# L3INIT_PRM register map
Vendor: Texas Instruments
Peripheral module from a debugger description file (folder omap4430).
Registers are 32-bit, access not given, reset 0x0 unless marked. A register's access mark holds for its fields unless they carry their own. Offsets are as the file gives them; lines under a group give offsets from that group; [hi:lo] are bit positions; {n}, {i} and the like mark numbered series; 'fields as' and 'values as' point back to an identical list; <NAME> marks a mode.

## L3INIT_PRM
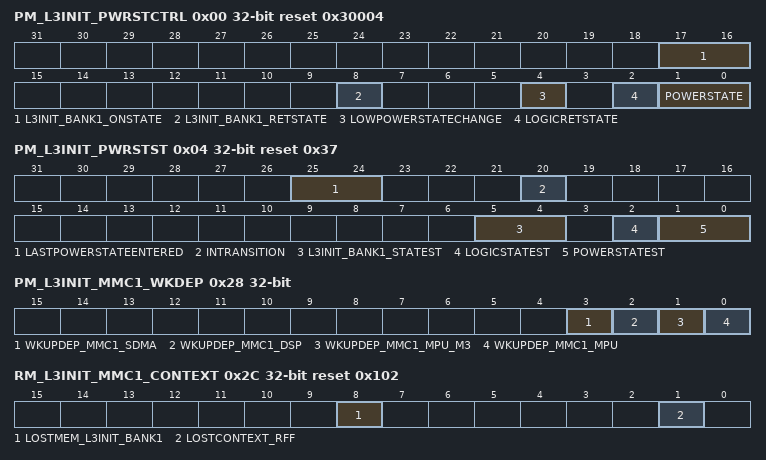
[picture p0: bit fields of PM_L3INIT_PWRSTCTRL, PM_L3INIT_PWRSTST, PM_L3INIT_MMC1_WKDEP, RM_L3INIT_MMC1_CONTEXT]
0x00 PM_L3INIT_PWRSTCTRL reset 0x30004 — This register controls the L3INIT power state to reach upon a domain sleep transition
  [17:16] L3INIT_BANK1_ONSTATE — L3INIT BANK state when domain is ON. (access R Rreturns1s)
    3=L3INIT_BANK1_ONSTATE_3_r (Memory bank is on when the domain is ON.)
  [8] L3INIT_BANK1_RETSTATE ro — L3INIT BANK1 state when domain is RETENTION.
    0=L3INIT_BANK1_RETSTATE_0_r (Memory bank is off when the domain is in the RETENTION state.)
  [4] LOWPOWERSTATECHANGE — Power state change request when domain has already performed a sleep transition. Allows going into deeper low power state without waking up the power domain. (access RW WSpecial)
    0=Do not request a low power state change; 1=Request a low power state change. This bit is automatically cleared when the power state is effectively changed or when power state is ON.
  [2] LOGICRETSTATE rw — Logic state when power domain is RETENTION
    0=Only retention registers are retained and remaing logic is off when the domain is in RETENTION state; 1=Whole logic is retained when domain is in RETENTION state
  [1:0] POWERSTATE rw — Power state control
    0=OFF state; 1=RETENTION state; 2=INACTIVE state; 3=ON State
0x04 PM_L3INIT_PWRSTST reset 0x37 — This register provides a status on the current L3INIT power domain state. [warm reset insensitive]
  [25:24] LASTPOWERSTATEENTERED — Last low power state entered. Set to 0x3 upon write of the same only. This register is intended for debug purpose only. (access RW W1toSet)
    3=LASTPOWERSTATEENTERED_3_r (Power domain was previously ON-ACTIVE); 2=LASTPOWERSTATEENTERED_2_r (Power domain was previously ON-INACTIVE); 1=LASTPOWERSTATEENTERED_1_r (Power domain was previously in RETENTION); 0=LASTPOWERSTATEENTERED_0_r (Power domain was previously OFF)
  [20] INTRANSITION ro — Domain transition status
    0=INTRANSITION_0_r (No ongoing transition on power domain); 1=INTRANSITION_1_r (Power domain transition is in progress.)
  [5:4] L3INIT_BANK1_STATEST ro — L3INIT BANK1 state status
    0=L3INIT_BANK1_STATEST_0_r (Memory is OFF); 1=L3INIT_BANK1_STATEST_1_r (Reserved); 2=L3INIT_BANK1_STATEST_2_r (Reserved); 3=L3INIT_BANK1_STATEST_3_r (Memory is ON)
  [2] LOGICSTATEST ro — Logic state status
    0=LOGICSTATEST_0_r (Logic in domain is OFF); 1=LOGICSTATEST_1_r (Logic in domain is ON)
  [1:0] POWERSTATEST ro — Current power state status
    0=POWERSTATEST_0_r (Power domain is OFF); 1=POWERSTATEST_1_r (Power domain is in RETENTION); 2=POWERSTATEST_2_r (Power domain is ON-INACTIVE); 3=POWERSTATEST_3_r (Power domain is ON-ACTIVE)
0x28 PM_L3INIT_MMC1_WKDEP access per field — This register controls wakeup dependency based on MMC1 service requests.
  [all] fields
    0=Dependency is disabled; 1=Dependency is enabled
  [3] WKUPDEP_MMC1_SDMA rw — Wakeup dependency from MMC1 module (softwareakeup signal) towards SDMA + L3_2 + L4PER domains
  [2] WKUPDEP_MMC1_DSP rw — Wakeup dependency from MMC1 module (softwareakeup signal) towards DSP + L3_1 + L3_2 + L4_PER domains
  [1] WKUPDEP_MMC1_MPU_M3 rw — Wakeup dependency from MMC1 module (softwareakeup signal) towards MPU_A3 + L3_2 + L4_PER domains
  [0] WKUPDEP_MMC1_MPU rw — Wakeup dependency from MMC1 module (softwareakeup signal) towards MPU + L3_1 + L3_2 + L4_PER domains
0x2C RM_L3INIT_MMC1_CONTEXT reset 0x102 — This register contains dedicated MMC1 context statuses. [warm reset insensitive]
  [8] LOSTMEM_L3INIT_BANK1 — Specify if memory-based context in L3INIT_BANK1 memory bank has been lost due to a previous power transition or other reset source. (access RW W1toClr)
    0=Context has been maintained; 1=Context has been lost
  [1] LOSTCONTEXT_RFF — Specify if RFF-based context has been lost due to a previous power transition or other reset source. (set upon assertion of L3_INIT_RET_RST signal) (access RW W1toClr)
    0=Context has been maintained; 1=Context has been lost
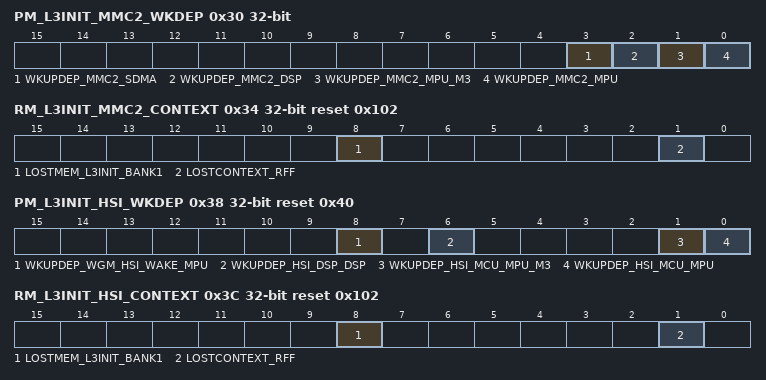
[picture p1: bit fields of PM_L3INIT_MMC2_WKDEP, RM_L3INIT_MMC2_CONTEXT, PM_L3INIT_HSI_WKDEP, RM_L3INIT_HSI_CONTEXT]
0x30 PM_L3INIT_MMC2_WKDEP access per field — This register controls wakeup dependency based on MMC2 service requests.
  [all] fields
    0=Dependency is disabled; 1=Dependency is enabled
  [3] WKUPDEP_MMC2_SDMA rw — Wakeup dependency from MMC2 module (softwareakeup signal) towards SDMA + L3_2 + L4PER domains
  [2] WKUPDEP_MMC2_DSP rw — Wakeup dependency from MMC2 module (softwareakeup signal) towards DSP + L3_1 + L3_2 + L4_PER domains
  [1] WKUPDEP_MMC2_MPU_M3 rw — Wakeup dependency from MMC2 module (softwareakeup signal) towards MPU_A3 + L3_2 + L4_PER domains
  [0] WKUPDEP_MMC2_MPU rw — Wakeup dependency from MMC2 module (softwareakeup signal) towards MPU + L3_1 + L3_2 + L4_PER domains
0x34 RM_L3INIT_MMC2_CONTEXT reset 0x102 — This register contains dedicated MMC2 context statuses. [warm reset insensitive]
  fields as RM_L3INIT_MMC1_CONTEXT
0x38 PM_L3INIT_HSI_WKDEP reset 0x40 — This register controls wakeup dependency based on HSI service requests.
  [8] WKUPDEP_WGM_HSI_WAKE_MPU rw — Wakeup dependency from modem HSI_WAKE signal towards MPU + L3_1 + L4_CFG domains
    0=Dependency is disabled; 1=Dependency is enabled
  [6] WKUPDEP_HSI_DSP_DSP — Wakeup dependency from HSI module (softwareakeup_DSP signal) towards DSP + L3_1 + L4_CFG domains (access R Rreturns1s)
    1=WKUPDEP_HSI_DSP_DSP_1_r (Dependency is enabled)
  [1] WKUPDEP_HSI_MCU_MPU_M3 rw — Wakeup dependency from HSI module (softwareakeup_MPU signal) towards MPU_A3 + L3_2 + L3_1 + L4_CFG domains
    0=Dependency is disabled; 1=Dependency is enabled
  [0] WKUPDEP_HSI_MCU_MPU rw — Wakeup dependency from HSI module (softwareakeup_MPU signal) towards MPU + L3_1 + L4_CFG domains
    0=Dependency is disabled; 1=Dependency is enabled
0x3C RM_L3INIT_HSI_CONTEXT reset 0x102 — This register contains dedicated HSI context statuses. [warm reset insensitive]
  fields as RM_L3INIT_MMC1_CONTEXT
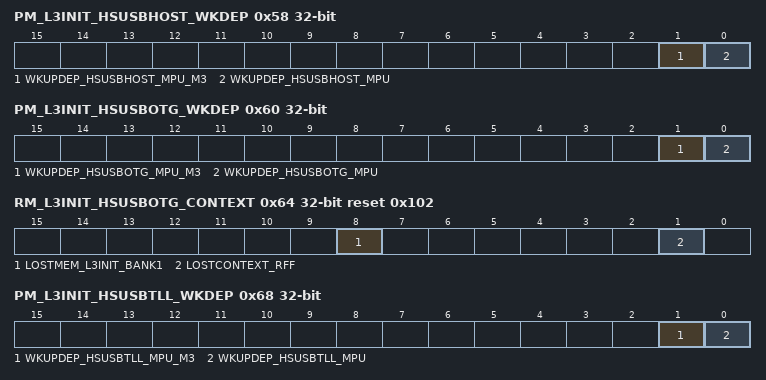
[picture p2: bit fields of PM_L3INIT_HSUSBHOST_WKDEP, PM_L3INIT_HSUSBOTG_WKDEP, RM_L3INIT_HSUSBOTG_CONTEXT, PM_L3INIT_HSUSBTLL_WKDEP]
0x58 PM_L3INIT_HSUSBHOST_WKDEP access per field — This register controls wakeup dependency based on USB_HOST_HS service requests.
  [1] WKUPDEP_HSUSBHOST_MPU_M3 rw — Wakeup dependency from USB_HOST_HS module (softwareakeup signal) towards MPU_A3 + L3_2 + L3_1 + L4_CFG domains
    0=Dependency is disabled; 1=Dependency is enabled
  [0] WKUPDEP_HSUSBHOST_MPU rw — Wakeup dependency from USB_HOST_HS module (softwareakeup signal) towards MPU + L3_1 + L4_CFG domains
    0=Dependency is disabled; 1=Dependency is enabled
0x5C RM_L3INIT_HSUSBHOST_CONTEXT reset 0x2 — This register contains dedicated USB_HOST context statuses. [warm reset insensitive]
  [1] LOSTCONTEXT_RFF — Specify if RFF-based context has been lost due to a previous power transition or other reset source. (set upon assertion of L3_INIT_RET_RST signal) (access RW W1toClr)
    0=Context has been maintained; 1=Context has been lost
0x60 PM_L3INIT_HSUSBOTG_WKDEP access per field — This register controls wakeup dependency based on USB_OTG_HS service requests.
  [1] WKUPDEP_HSUSBOTG_MPU_M3 rw — Wakeup dependency from USB_OTG_HS module (softwareakeup signal) towards MPU_A3 + L3_2 + L3_1 + L4_CFG domains
    0=Dependency is disabled; 1=Dependency is enabled
  [0] WKUPDEP_HSUSBOTG_MPU rw — Wakeup dependency from USB_OTG_HS module (softwareakeup signal) towards MPU + L3_1 + L4_CFG domains
    0=Dependency is disabled; 1=Dependency is enabled
0x64 RM_L3INIT_HSUSBOTG_CONTEXT reset 0x102 — This register contains dedicated USB_OTG_HS context statuses. [warm reset insensitive]
  fields as RM_L3INIT_MMC1_CONTEXT
0x68 PM_L3INIT_HSUSBTLL_WKDEP access per field — This register controls wakeup dependency based on USB_TLL service requests.
  [1] WKUPDEP_HSUSBTLL_MPU_M3 rw — Wakeup dependency from USB_TLL module (softwareakeup signal) towards MPU_A3 + L3_2 + L3_1 + L4_CFG domains
    0=Dependency is disabled; 1=Dependency is enabled
  [0] WKUPDEP_HSUSBTLL_MPU rw — Wakeup dependency from USB_TLL module (softwareakeup signal) towards MPU + L3_1 + L4_CFG domains
    0=Dependency is disabled; 1=Dependency is enabled
0x6C RM_L3INIT_HSUSBTLL_CONTEXT reset 0x2 — This register contains dedicated USB_TLL context statuses. [warm reset insensitive]
  fields as RM_L3INIT_HSUSBHOST_CONTEXT
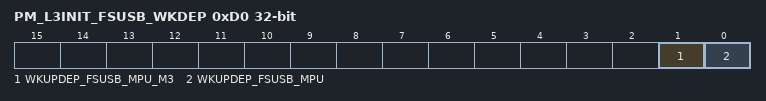
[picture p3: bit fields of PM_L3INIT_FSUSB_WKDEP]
0xD0 PM_L3INIT_FSUSB_WKDEP access per field — This register controls wakeup dependency based on USB_HOST_FS service requests.
  [1] WKUPDEP_FSUSB_MPU_M3 rw — Wakeup dependency from USB_HOST_FS module (softwareakeup signal) towards MPU_A3 + L3_2 + L3_1 + L4_CFG domains
    0=Dependency is disabled; 1=Dependency is enabled
  [0] WKUPDEP_FSUSB_MPU rw — Wakeup dependency from USB_HOST_FS module (softwareakeup signal) towards MPU + L3_1 + L4_CFG domains
    0=Dependency is disabled; 1=Dependency is enabled
0xD4 RM_L3INIT_FSUSB_CONTEXT reset 0x2 — This register contains dedicated USB_HOST_FS context statuses. [warm reset insensitive]
  fields as RM_L3INIT_HSUSBHOST_CONTEXT
0xE4 RM_L3INIT_USBPHY_CONTEXT reset 0x1 — This register contains dedicated USBPHY context statuses. [warm reset insensitive]
  [0] LOSTCONTEXT_DFF — Specify if DFF-based context has been lost due to a previous power transition or other reset source. (set upon assertion of L3_INIT_RST signal) (access RW W1toClr)
    0=Context has been maintained; 1=Context has been lost
